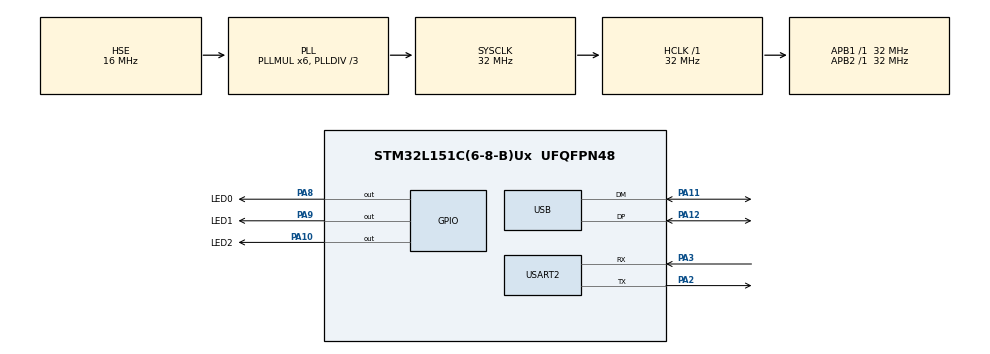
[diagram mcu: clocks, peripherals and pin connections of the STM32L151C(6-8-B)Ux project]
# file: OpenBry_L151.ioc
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Dma.Request0=USART2_RX
Dma.USART2_RX.0.Direction=DMA_PERIPH_TO_MEMORY
Dma.USART2_RX.0.Instance=DMA1_Channel6
Dma.USART2_RX.0.MemDataAlignment=DMA_MDATAALIGN_BYTE
Dma.USART2_RX.0.MemInc=DMA_MINC_ENABLE
Dma.USART2_RX.0.Mode=DMA_NORMAL
Dma.USART2_RX.0.PeriphDataAlignment=DMA_PDATAALIGN_BYTE
Dma.USART2_RX.0.PeriphInc=DMA_PINC_DISABLE
Dma.USART2_RX.0.Priority=DMA_PRIORITY_LOW
Mcu.Family=STM32L1
Mcu.Name=STM32L151C(6-8-B)Ux
Mcu.Package=UFQFPN48
NVIC.DMA1_Channel6_IRQn=true\:0\:0\:false\:false\:true
NVIC.PriorityGroup=NVIC_PRIORITYGROUP_4
NVIC.USART2_IRQn=true\:1\:0\:true\:true\:true\:2
NVIC.USB_LP_IRQn=true\:0\:0\:false\:true\:true\:1
PA10.GPIO_Label=LED2
PA10.Signal=GPIO_Output
PA11.Mode=Device
PA11.Signal=USB_DM
PA12.Mode=Device
PA12.Signal=USB_DP
PA2.Mode=Asynchronous
PA2.Signal=USART2_TX
PA3.Mode=Asynchronous
PA3.Signal=USART2_RX
PA8.GPIO_Label=LED0
PA8.Signal=GPIO_Output
PA9.GPIO_Label=LED1
PA9.Signal=GPIO_Output
PH0-OSC_IN.Mode=HSE-External-Oscillator
PH0-OSC_IN.Signal=RCC_OSC_IN
PH1-OSC_OUT.Mode=HSE-External-Oscillator
PH1-OSC_OUT.Signal=RCC_OSC_OUT
ProjectManager.HeapSize=0x200
ProjectManager.StackSize=0x400
ProjectManager.TargetToolchain=SW4STM32
RCC.ADCEnable=false
RCC.AHBFreq_Value=32000000
RCC.APB1Freq_Value=32000000
RCC.APB1TimFreq_Value=32000000
RCC.APB2Freq_Value=32000000
RCC.APB2TimFreq_Value=32000000
RCC.EnableCSSLSE=false
RCC.EnableHSE=true
RCC.EnableHSELCDDevisor=false
RCC.EnableHSERTCDevisor=false
RCC.EnableLSE=false
RCC.EnableLSERTC=false
RCC.EnbaleCSS=false
RCC.HCLKFreq_Value=32000000
RCC.HSEState=RCC_HSE_ON
RCC.HSE_VALUE=16000000
RCC.HSIState=RCC_HSI_ON
RCC.HSI_VALUE=16000000
RCC.IWDGEnable=false
RCC.LCDEnable=false
RCC.LSE_VALUE=32768
RCC.LSIState=RCC_LSI_OFF
RCC.MCOEnable=false
RCC.MSI_VALUE=2097000
RCC.OscillatorTypeHSE=RCC_OSCILLATORTYPE_HSE
RCC.OscillatorTypeHSI=RCC_OSCILLATORTYPE_HSI
RCC.OscillatorTypeMSI=RCC_OSCILLATORTYPE_MSI
RCC.PLLDIV=RCC_PLL_DIV3
RCC.PLLMUL=RCC_PLL_MUL6
RCC.PLLSource=RCC_PLLSOURCE_HSE
RCC.PLLSourceVirtual=RCC_PLLSOURCE_HSE
RCC.PLLState=RCC_PLL_ON
RCC.RTCEnable=false
RCC.SYSCLKFreq_VALUE=32000000
RCC.SYSCLKSource=RCC_SYSCLKSOURCE_PLLCLK
RCC.USBEnable=true
RCC.USBOutput=48000000
RCC.VCOOutputFreq_Value=96000000
USART2.HwFlowCtl-Asynchronous=UART_HWCONTROL_NONE
USART2.VirtualMode=VM_ASYNC
USB_DEVICE.CLASS_NAME_FS=CDC
USB_DEVICE.USBD_HandleTypeDef_FS=hUsbDevice_USB_FS
USB_DEVICE.VirtualMode=Cdc
USB_DEVICE.VirtualModeFS=Cdc_FS
VP_USB_DEVICE_VS_USB_DEVICE_CDC_FS.Mode=CDC_FS
board=OpenBry_L151

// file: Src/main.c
/**
  ******************************************************************************
  * File Name          : main.c
  * Description        : Main program body
  ******************************************************************************
  *
  * Copyright (c) 2017 STMicroelectronics International N.V.
  * All rights reserved.
  *
  * Redistribution and use in source and binary forms, with or without
  * modification, are permitted, provided that the following conditions are met:
  *
  * 1. Redistribution of source code must retain the above copyright notice,
  *    this list of conditions and the following disclaimer.
  * 2. Redistributions in binary form must reproduce the above copyright notice,
  *    this list of conditions and the following disclaimer in the documentation
  *    and/or other materials provided with the distribution.
  * 3. Neither the name of STMicroelectronics nor the names of other
  *    contributors to this software may be used to endorse or promote products
  *    derived from this software without specific written permission.
  * 4. This software, including modifications and/or derivative works of this
  *    software, must execute solely and exclusively on microcontroller or
  *    microprocessor devices manufactured by or for STMicroelectronics.
  * 5. Redistribution and use of this software other than as permitted under
  *    this license is void and will automatically terminate your rights under
  *    this license.
  *
  * THIS SOFTWARE IS PROVIDED BY STMICROELECTRONICS AND CONTRIBUTORS "AS IS"
  * AND ANY EXPRESS, IMPLIED OR STATUTORY WARRANTIES, INCLUDING, BUT NOT
  * LIMITED TO, THE IMPLIED WARRANTIES OF MERCHANTABILITY, FITNESS FOR A
  * PARTICULAR PURPOSE AND NON-INFRINGEMENT OF THIRD PARTY INTELLECTUAL PROPERTY
  * RIGHTS ARE DISCLAIMED TO THE FULLEST EXTENT PERMITTED BY LAW. IN NO EVENT
  * SHALL STMICROELECTRONICS OR CONTRIBUTORS BE LIABLE FOR ANY DIRECT, INDIRECT,
  * INCIDENTAL, SPECIAL, EXEMPLARY, OR CONSEQUENTIAL DAMAGES (INCLUDING, BUT NOT
  * LIMITED TO, PROCUREMENT OF SUBSTITUTE GOODS OR SERVICES; LOSS OF USE, DATA,
  * OR PROFITS; OR BUSINESS INTERRUPTION) HOWEVER CAUSED AND ON ANY THEORY OF
  * LIABILITY, WHETHER IN CONTRACT, STRICT LIABILITY, OR TORT (INCLUDING
  * NEGLIGENCE OR OTHERWISE) ARISING IN ANY WAY OUT OF THE USE OF THIS SOFTWARE,
  * EVEN IF ADVISED OF THE POSSIBILITY OF SUCH DAMAGE.
  *
  ******************************************************************************
  */
#include "main.h"
#include "stm32l1xx_hal.h"
#include "dma.h"
#include "usart.h"
#include "usb_device.h"
#include "gpio.h"

/* USER CODE BEGIN PV */
/* Private variables ---------------------------------------------------------*/

/* USER CODE END PV */

void SystemClock_Config(void);
void Error_Handler(void);
static void MX_NVIC_Init(void);

/* USER CODE BEGIN PFP */
/* Private function prototypes -----------------------------------------------*/

/* USER CODE END PFP */

int main(void)
{

  /* MCU Configuration----------------------------------------------------------*/

  /* Reset of all peripherals, Initializes the Flash interface and the Systick. */
  HAL_Init();

  /* Configure the system clock */
  SystemClock_Config();

  /* Initialize all configured peripherals */
  MX_GPIO_Init();
  MX_DMA_Init();
  MX_USART2_UART_Init();
  MX_USB_DEVICE_Init();

  /* Initialize interrupts */
  MX_NVIC_Init();

  /* USER CODE BEGIN 2 */
char buf[100];
uint32_t i=0;
  /* USER CODE END 2 */

  /* Infinite loop */
  while (1)
  {

  /* USER CODE BEGIN 3 */
	  HAL_Delay(100);

	  printf("%d\n" ,i++);

	 scanf("%d\n", &i);

  }
  /* USER CODE END 3 */

}

/** System Clock Configuration
*/
void SystemClock_Config(void)
{

  RCC_OscInitTypeDef RCC_OscInitStruct;
  RCC_ClkInitTypeDef RCC_ClkInitStruct;

    /**Configure the main internal regulator output voltage
    */
  __HAL_PWR_VOLTAGESCALING_CONFIG(PWR_REGULATOR_VOLTAGE_SCALE1);

    /**Initializes the CPU, AHB and APB busses clocks
    */
  RCC_OscInitStruct.OscillatorType = RCC_OSCILLATORTYPE_HSI|RCC_OSCILLATORTYPE_HSE;
  RCC_OscInitStruct.HSEState = RCC_HSE_ON;
  RCC_OscInitStruct.PLL.PLLState = RCC_PLL_ON;
  RCC_OscInitStruct.PLL.PLLSource = RCC_PLLSOURCE_HSE;
  RCC_OscInitStruct.PLL.PLLMUL = RCC_PLL_MUL6;
  RCC_OscInitStruct.PLL.PLLDIV = RCC_PLL_DIV3;
  if (HAL_RCC_OscConfig(&RCC_OscInitStruct) != HAL_OK)
  {
    Error_Handler();
  }

    /**Initializes the CPU, AHB and APB busses clocks
    */
  RCC_ClkInitStruct.ClockType = RCC_CLOCKTYPE_HCLK|RCC_CLOCKTYPE_SYSCLK
                              |RCC_CLOCKTYPE_PCLK1|RCC_CLOCKTYPE_PCLK2;
  RCC_ClkInitStruct.SYSCLKSource = RCC_SYSCLKSOURCE_PLLCLK;
  RCC_ClkInitStruct.AHBCLKDivider = RCC_SYSCLK_DIV1;
  RCC_ClkInitStruct.APB1CLKDivider = RCC_HCLK_DIV1;
  RCC_ClkInitStruct.APB2CLKDivider = RCC_HCLK_DIV1;

  if (HAL_RCC_ClockConfig(&RCC_ClkInitStruct, FLASH_LATENCY_1) != HAL_OK)
  {
    Error_Handler();
  }

    /**Configure the Systick interrupt time
    */
  HAL_SYSTICK_Config(HAL_RCC_GetHCLKFreq()/1000);

    /**Configure the Systick
    */
  HAL_SYSTICK_CLKSourceConfig(SYSTICK_CLKSOURCE_HCLK);

  /* SysTick_IRQn interrupt configuration */
  HAL_NVIC_SetPriority(SysTick_IRQn, 0, 0);
}

/** NVIC Configuration
*/
static void MX_NVIC_Init(void)
{
  /* USB_LP_IRQn interrupt configuration */
  HAL_NVIC_SetPriority(USB_LP_IRQn, 0, 0);
  HAL_NVIC_EnableIRQ(USB_LP_IRQn);
  /* USART2_IRQn interrupt configuration */
  HAL_NVIC_SetPriority(USART2_IRQn, 1, 0);
  HAL_NVIC_EnableIRQ(USART2_IRQn);
}

void Error_Handler(void)
{
  while(1)
  {
  }
}

/************************ (C) COPYRIGHT STMicroelectronics *****END OF FILE****/
